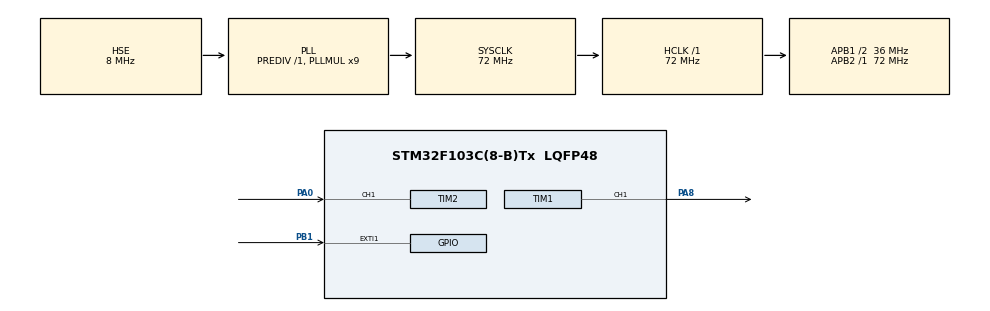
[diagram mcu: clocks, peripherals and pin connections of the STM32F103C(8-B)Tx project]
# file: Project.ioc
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Mcu.Family=STM32F1
Mcu.Name=STM32F103C(8-B)Tx
Mcu.Package=LQFP48
NVIC.EXTI1_IRQn=true\:0\:0\:false\:false\:true\:true\:true\:true
NVIC.PriorityGroup=NVIC_PRIORITYGROUP_4
NVIC.TIM2_IRQn=true\:0\:0\:false\:false\:true\:true\:true\:true
PA0-WKUP.Signal=S_TIM2_CH1_ETR
PA13.Mode=Serial_Wire
PA13.Signal=SYS_JTMS-SWDIO
PA14.Mode=Serial_Wire
PA14.Signal=SYS_JTCK-SWCLK
PA8.Signal=S_TIM1_CH1
PB1.GPIO_ModeDefaultEXTI=GPIO_MODE_IT_FALLING
PB1.GPIO_PuPd=GPIO_PULLUP
PB1.Signal=GPXTI1
PD0-OSC_IN.Mode=HSE-External-Oscillator
PD0-OSC_IN.Signal=RCC_OSC_IN
PD1-OSC_OUT.Mode=HSE-External-Oscillator
PD1-OSC_OUT.Signal=RCC_OSC_OUT
ProjectManager.HeapSize=0x200
ProjectManager.StackSize=0x400
ProjectManager.TargetToolchain=MDK-ARM V5.32
RCC.AHBFreq_Value=72000000
RCC.APB1CLKDivider=RCC_HCLK_DIV2
RCC.APB1Freq_Value=36000000
RCC.APB1TimFreq_Value=72000000
RCC.APB2Freq_Value=72000000
RCC.APB2TimFreq_Value=72000000
RCC.HCLKFreq_Value=72000000
RCC.PLLMUL=RCC_PLL_MUL9
RCC.PLLSourceVirtual=RCC_PLLSOURCE_HSE
RCC.SYSCLKFreq_VALUE=72000000
RCC.SYSCLKSource=RCC_SYSCLKSOURCE_PLLCLK
RCC.USBFreq_Value=72000000
SH.S_TIM1_CH1.0=TIM1_CH1,PWM Generation1 CH1
SH.S_TIM2_CH1_ETR.0=TIM2_CH1,Input_Capture1_from_TI1
SH.S_TIM2_CH1_ETR.1=TIM2_CH1,TriggerSource_TI1FP1
TIM1.AutoReloadPreload=TIM_AUTORELOAD_PRELOAD_ENABLE
TIM1.Channel-PWM\ Generation1\ CH1=TIM_CHANNEL_1
TIM1.OCFastMode_PWM-PWM\ Generation1\ CH1=TIM_OCFAST_DISABLE
TIM1.Period=999
TIM1.Prescaler=71
TIM1.Pulse-PWM\ Generation1\ CH1=500
TIM2.Channel-Input_Capture1_from_TI1=TIM_CHANNEL_1
TIM2.Channel-Input_Capture2_from_TI1_63=TIM_CHANNEL_2
TIM2.ICPolarity_CH2=TIM_INPUTCHANNELPOLARITY_FALLING
TIM2.Prescaler=71
VP_TIM1_VS_ClockSourceINT.Mode=Internal
VP_TIM2_VS_ClockSourceINT.Mode=Internal
VP_TIM2_VS_ControllerModeReset.Mode=Reset Mode
VP_TIM2_VS_indirect_ch1.Mode=Input_Capture2_from_TI1_63
board=custom

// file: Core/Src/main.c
/* USER CODE BEGIN Header */
/**
  ******************************************************************************
  * @file           : main.c
  * @brief          : Main program body
  ******************************************************************************
  * @attention
  *
  * Copyright (c) 2026 STMicroelectronics.
  * All rights reserved.
  *
  * This software is licensed under terms that can be found in the LICENSE file
  * in the root directory of this software component.
  * If no LICENSE file comes with this software, it is provided AS-IS.
  *
  ******************************************************************************
  */
/* USER CODE END Header */
#include "main.h"
#include "tim.h"
#include "gpio.h"

/* USER CODE BEGIN Includes */
#include "OLED.h"
#include "LED.h"
#include "Key.h"
/* USER CODE END Includes */

/* USER CODE BEGIN PV */
float PWM_Freq = 0;
float PWM_Duty = 0;
uint16_t CCR1_Val = 0;
uint16_t CCR2_Val = 0;
uint16_t TIM1_CCR1 = 500;
/* USER CODE END PV */

void SystemClock_Config(void);

int main(void)
{

  /* MCU Configuration--------------------------------------------------------*/

  /* Reset of all peripherals, Initializes the Flash interface and the Systick. */
  HAL_Init();

  /* USER CODE BEGIN Init */
	OLED_Init();	//初始化OLED
  /* USER CODE END Init */

  /* Configure the system clock */
  SystemClock_Config();

  /* Initialize all configured peripherals */
  MX_GPIO_Init();
  MX_TIM1_Init();
  MX_TIM2_Init();
  /* USER CODE BEGIN 2 */
  HAL_TIM_PWM_Start(&htim1, TIM_CHANNEL_1);  // 启动TIM1 CH1 PWM输出，不开没输出！
  HAL_TIM_IC_Start_IT(&htim2, TIM_CHANNEL_1);  // 启动TIM2 CNT，CH1输入捕获与中断
  HAL_TIM_IC_Start_IT(&htim2, TIM_CHANNEL_2);  // 启动CH2
  OLED_ShowString(1, 1, "Out:1kHz       %");
  OLED_ShowDecimalNum(1, 10, HAL_TIM_ReadCapturedValue(&htim1, TIM_CHANNEL_1) / 1000.0 * 100, 2);
  OLED_ShowString(2, 1, "PWMI");
  OLED_ShowString(3, 1, "Freq:       Hz");
  OLED_ShowString(4, 1, "Duty:       %");
  /* USER CODE END 2 */

  /* Infinite loop */
  /* USER CODE BEGIN WHILE */

  while (1)
  {
	if (Key1_Flag == 1){
		TIM1_CCR1+=10;	//占空比+1%
		__HAL_TIM_SET_COMPARE(&htim1, TIM_CHANNEL_1, TIM1_CCR1);		//修改TIM1 CH1输出占空比
		OLED_ShowDecimalNum(1, 10, HAL_TIM_ReadCapturedValue(&htim1, TIM_CHANNEL_1) / 1000.0 * 100, 2);
		Key1_ITHandle();
	}
	OLED_ShowDecimalNum(3, 7, PWM_Freq, 1);
	OLED_ShowDecimalNum(4, 7, PWM_Duty, 2);
    /* USER CODE END WHILE */

  }
}

void SystemClock_Config(void)
{
  RCC_OscInitTypeDef RCC_OscInitStruct = {0};
  RCC_ClkInitTypeDef RCC_ClkInitStruct = {0};

  /** Initializes the RCC Oscillators according to the specified parameters
  * in the RCC_OscInitTypeDef structure.
  */
  RCC_OscInitStruct.OscillatorType = RCC_OSCILLATORTYPE_HSE;
  RCC_OscInitStruct.HSEState = RCC_HSE_ON;
  RCC_OscInitStruct.HSEPredivValue = RCC_HSE_PREDIV_DIV1;
  RCC_OscInitStruct.HSIState = RCC_HSI_ON;
  RCC_OscInitStruct.PLL.PLLState = RCC_PLL_ON;
  RCC_OscInitStruct.PLL.PLLSource = RCC_PLLSOURCE_HSE;
  RCC_OscInitStruct.PLL.PLLMUL = RCC_PLL_MUL9;
  if (HAL_RCC_OscConfig(&RCC_OscInitStruct) != HAL_OK)
  {
    Error_Handler();
  }

  /** Initializes the CPU, AHB and APB buses clocks
  */
  RCC_ClkInitStruct.ClockType = RCC_CLOCKTYPE_HCLK|RCC_CLOCKTYPE_SYSCLK
                              |RCC_CLOCKTYPE_PCLK1|RCC_CLOCKTYPE_PCLK2;
  RCC_ClkInitStruct.SYSCLKSource = RCC_SYSCLKSOURCE_PLLCLK;
  RCC_ClkInitStruct.AHBCLKDivider = RCC_SYSCLK_DIV1;
  RCC_ClkInitStruct.APB1CLKDivider = RCC_HCLK_DIV2;
  RCC_ClkInitStruct.APB2CLKDivider = RCC_HCLK_DIV1;

  if (HAL_RCC_ClockConfig(&RCC_ClkInitStruct, FLASH_LATENCY_2) != HAL_OK)
  {
    Error_Handler();
  }
}

/* USER CODE BEGIN 4 */
void HAL_TIM_IC_CaptureCallback(TIM_HandleTypeDef* htim){
	if (htim->Instance == TIM2){
		if (htim->Channel == HAL_TIM_ACTIVE_CHANNEL_1){		//注意检测的Channel名字！！！通道一上升沿，用CCR1值测量频率
			CCR1_Val = HAL_TIM_ReadCapturedValue(htim, TIM_CHANNEL_1);
			if (CCR1_Val > 0){
				PWM_Freq = SystemCoreClock / 72.0 / CCR1_Val;	//测周法测频，Freq=F(tim)/CCR1;
			}
		}
		else if (htim->Channel == HAL_TIM_ACTIVE_CHANNEL_2){	//通道二下降沿，用CCR2值测量频率
			CCR2_Val = HAL_TIM_ReadCapturedValue(htim, TIM_CHANNEL_2);	//占空比=CCR2/CCR1 * 100%
			if (CCR2_Val > 0){
				PWM_Duty = (float)CCR2_Val / CCR1_Val * 100.0;	//测量占空比
			}
		}
	}
}
/* USER CODE END 4 */

void Error_Handler(void)
{
  __disable_irq();
  while (1)
  {
  }
}
